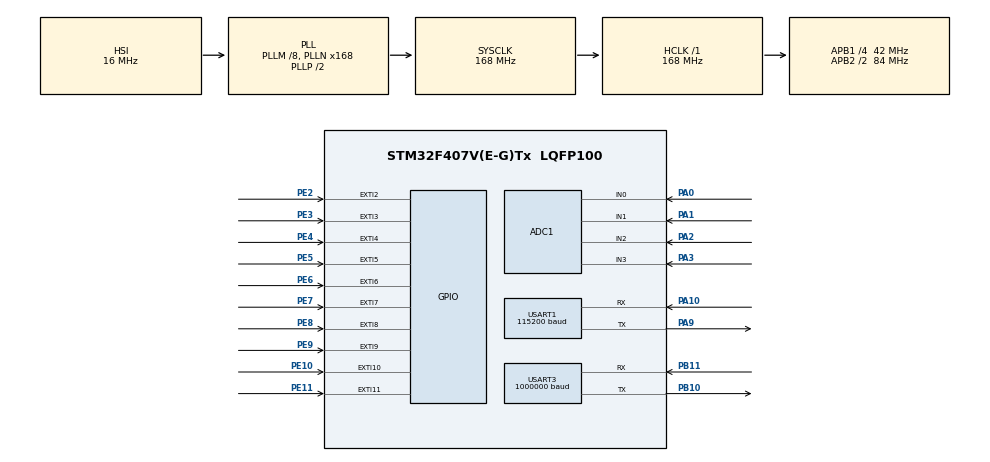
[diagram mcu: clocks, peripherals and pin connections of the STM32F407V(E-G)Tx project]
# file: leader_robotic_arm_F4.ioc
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ADC1.Channel-0\#ChannelRegularConversion=ADC_CHANNEL_0
ADC1.Channel-1\#ChannelRegularConversion=ADC_CHANNEL_1
ADC1.Channel-2\#ChannelRegularConversion=ADC_CHANNEL_2
ADC1.Channel-3\#ChannelRegularConversion=ADC_CHANNEL_3
ADC1.ContinuousConvMode=ENABLE
ADC1.DMAContinuousRequests=ENABLE
ADC1.NbrOfConversion=4
ADC1.NbrOfConversionFlag=1
ADC1.Rank-0\#ChannelRegularConversion=1
ADC1.Rank-1\#ChannelRegularConversion=2
ADC1.Rank-2\#ChannelRegularConversion=3
ADC1.Rank-3\#ChannelRegularConversion=4
ADC1.SamplingTime-0\#ChannelRegularConversion=ADC_SAMPLETIME_28CYCLES
ADC1.SamplingTime-1\#ChannelRegularConversion=ADC_SAMPLETIME_28CYCLES
ADC1.SamplingTime-2\#ChannelRegularConversion=ADC_SAMPLETIME_28CYCLES
ADC1.SamplingTime-3\#ChannelRegularConversion=ADC_SAMPLETIME_28CYCLES
ADC1.master=1
Dma.ADC1.0.Direction=DMA_PERIPH_TO_MEMORY
Dma.ADC1.0.FIFOMode=DMA_FIFOMODE_DISABLE
Dma.ADC1.0.Instance=DMA2_Stream0
Dma.ADC1.0.MemDataAlignment=DMA_MDATAALIGN_HALFWORD
Dma.ADC1.0.MemInc=DMA_MINC_ENABLE
Dma.ADC1.0.Mode=DMA_CIRCULAR
Dma.ADC1.0.PeriphDataAlignment=DMA_PDATAALIGN_HALFWORD
Dma.ADC1.0.PeriphInc=DMA_PINC_DISABLE
Dma.ADC1.0.Priority=DMA_PRIORITY_HIGH
Dma.Request0=ADC1
Mcu.Family=STM32F4
Mcu.Name=STM32F407V(E-G)Tx
Mcu.Package=LQFP100
NVIC.DMA2_Stream0_IRQn=true\:0\:0\:false\:false\:true\:false\:true\:true
NVIC.EXTI15_10_IRQn=true\:0\:0\:false\:false\:true\:true\:true\:true
NVIC.EXTI2_IRQn=true\:0\:0\:false\:false\:true\:true\:true\:true
NVIC.EXTI3_IRQn=true\:0\:0\:false\:false\:true\:true\:true\:true
NVIC.EXTI4_IRQn=true\:0\:0\:false\:false\:true\:true\:true\:true
NVIC.EXTI9_5_IRQn=true\:0\:0\:false\:false\:true\:true\:true\:true
NVIC.PriorityGroup=NVIC_PRIORITYGROUP_4
NVIC.USART1_IRQn=true\:0\:0\:false\:false\:true\:true\:true\:true
NVIC.USART3_IRQn=true\:0\:0\:false\:false\:true\:true\:true\:true
PA0-WKUP.Signal=ADCx_IN0
PA1.Signal=ADCx_IN1
PA10.Mode=Asynchronous
PA10.Signal=USART1_RX
PA13.Mode=Serial_Wire
PA13.Signal=SYS_JTMS-SWDIO
PA14.Mode=Serial_Wire
PA14.Signal=SYS_JTCK-SWCLK
PA2.Signal=ADCx_IN2
PA3.Signal=ADCx_IN3
PA9.Mode=Asynchronous
PA9.Signal=USART1_TX
PB10.Mode=Asynchronous
PB10.Signal=USART3_TX
PB11.Mode=Asynchronous
PB11.Signal=USART3_RX
PE10.GPIO_ModeDefaultEXTI=GPIO_MODE_IT_RISING_FALLING
PE10.GPIO_PuPd=GPIO_PULLUP
PE10.Signal=GPXTI10
PE11.GPIO_ModeDefaultEXTI=GPIO_MODE_IT_RISING_FALLING
PE11.GPIO_PuPd=GPIO_PULLUP
PE11.Signal=GPXTI11
PE2.GPIO_ModeDefaultEXTI=GPIO_MODE_IT_RISING_FALLING
PE2.GPIO_PuPd=GPIO_PULLUP
PE2.Signal=GPXTI2
PE3.GPIO_ModeDefaultEXTI=GPIO_MODE_IT_RISING_FALLING
PE3.GPIO_PuPd=GPIO_PULLUP
PE3.Signal=GPXTI3
PE4.GPIO_ModeDefaultEXTI=GPIO_MODE_IT_RISING_FALLING
PE4.GPIO_PuPd=GPIO_PULLUP
PE4.Signal=GPXTI4
PE5.GPIO_ModeDefaultEXTI=GPIO_MODE_IT_RISING_FALLING
PE5.GPIO_PuPd=GPIO_PULLUP
PE5.Signal=GPXTI5
PE6.GPIO_ModeDefaultEXTI=GPIO_MODE_IT_RISING_FALLING
PE6.GPIO_PuPd=GPIO_PULLUP
PE6.Signal=GPXTI6
PE7.GPIO_ModeDefaultEXTI=GPIO_MODE_IT_RISING_FALLING
PE7.GPIO_PuPd=GPIO_PULLUP
PE7.Signal=GPXTI7
PE8.GPIO_ModeDefaultEXTI=GPIO_MODE_IT_RISING_FALLING
PE8.GPIO_PuPd=GPIO_PULLUP
PE8.Signal=GPXTI8
PE9.GPIO_ModeDefaultEXTI=GPIO_MODE_IT_RISING_FALLING
PE9.GPIO_PuPd=GPIO_PULLUP
PE9.Signal=GPXTI9
PH0-OSC_IN.Mode=HSE-External-Oscillator
PH0-OSC_IN.Signal=RCC_OSC_IN
PH1-OSC_OUT.Mode=HSE-External-Oscillator
PH1-OSC_OUT.Signal=RCC_OSC_OUT
ProjectManager.HeapSize=0x200
ProjectManager.StackSize=0x400
ProjectManager.TargetToolchain=CMake
RCC.48MHZClocksFreq_Value=84000000
RCC.AHBFreq_Value=168000000
RCC.APB1CLKDivider=RCC_HCLK_DIV4
RCC.APB1Freq_Value=42000000
RCC.APB1TimFreq_Value=84000000
RCC.APB2CLKDivider=RCC_HCLK_DIV2
RCC.APB2Freq_Value=84000000
RCC.APB2TimFreq_Value=168000000
RCC.CortexFreq_Value=168000000
RCC.FLatency=FLASH_LATENCY_5
RCC.HCLKFreq_Value=168000000
RCC.HSE_VALUE=25000000
RCC.HSI_VALUE=16000000
RCC.LSE_VALUE=32768
RCC.PLLM=8
RCC.PLLN=168
RCC.SYSCLKFreq_VALUE=168000000
RCC.SYSCLKSource=RCC_SYSCLKSOURCE_PLLCLK
RCC.VCOOutputFreq_Value=336000000
SH.ADCx_IN0.0=ADC1_IN0,IN0
SH.ADCx_IN1.0=ADC1_IN1,IN1
SH.ADCx_IN2.0=ADC1_IN2,IN2
SH.ADCx_IN3.0=ADC1_IN3,IN3
USART1.BaudRate=115200
USART1.Mode=MODE_TX_RX
USART1.Parity=PARITY_NONE
USART1.StopBits=STOPBITS_1
USART1.VirtualMode=VM_ASYNC
USART1.WordLength=WORDLENGTH_8B
USART3.BaudRate=1000000
USART3.VirtualMode=VM_ASYNC
board=custom

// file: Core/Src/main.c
/* USER CODE BEGIN Header */
/**
  ******************************************************************************
  * @file           : main.c
  * @brief          : Main program body
  ******************************************************************************
  * @attention
  *
  * Copyright (c) 2026 STMicroelectronics.
  * All rights reserved.
  *
  * This software is licensed under terms that can be found in the LICENSE file
  * in the root directory of this software component.
  * If no LICENSE file comes with this software, it is provided AS-IS.
  *
  ******************************************************************************
  */
/* USER CODE END Header */
#include "main.h"
#include "adc.h"
#include "dma.h"
#include "usart.h"
#include "gpio.h"

/* USER CODE BEGIN Includes */
#include "control_task.h"
#include <stdint.h>
/* USER CODE END Includes */

void SystemClock_Config(void);

int main(void)
{

  /* MCU Configuration--------------------------------------------------------*/

  /* Reset of all peripherals, Initializes the Flash interface and the Systick. */
  HAL_Init();

  /* Configure the system clock */
  SystemClock_Config();

  /* Initialize all configured peripherals */
  MX_GPIO_Init();
  MX_DMA_Init();
  MX_USART1_UART_Init();
  MX_ADC1_Init();
  MX_USART3_UART_Init();
  /* USER CODE BEGIN 2 */

  control_task_init();

  /* USER CODE END 2 */

  /* Infinite loop */
  /* USER CODE BEGIN WHILE */
  while (1)
  {
    int start_time = HAL_GetTick();

    control_task_update();

    /* USER CODE END WHILE */

    /* USER CODE BEGIN 3 */
    int sleep_time = 1/60.0*1000 - (HAL_GetTick() - start_time);
    if(sleep_time > 0)
    {
        HAL_Delay( sleep_time);
    }
  }
  /* USER CODE END 3 */
}

void SystemClock_Config(void)
{
  RCC_OscInitTypeDef RCC_OscInitStruct = {0};
  RCC_ClkInitTypeDef RCC_ClkInitStruct = {0};

  /** Configure the main internal regulator output voltage
  */
  __HAL_RCC_PWR_CLK_ENABLE();
  __HAL_PWR_VOLTAGESCALING_CONFIG(PWR_REGULATOR_VOLTAGE_SCALE1);

  /** Initializes the RCC Oscillators according to the specified parameters
  * in the RCC_OscInitTypeDef structure.
  */
  RCC_OscInitStruct.OscillatorType = RCC_OSCILLATORTYPE_HSI;
  RCC_OscInitStruct.HSIState = RCC_HSI_ON;
  RCC_OscInitStruct.HSICalibrationValue = RCC_HSICALIBRATION_DEFAULT;
  RCC_OscInitStruct.PLL.PLLState = RCC_PLL_ON;
  RCC_OscInitStruct.PLL.PLLSource = RCC_PLLSOURCE_HSI;
  RCC_OscInitStruct.PLL.PLLM = 8;
  RCC_OscInitStruct.PLL.PLLN = 168;
  RCC_OscInitStruct.PLL.PLLP = RCC_PLLP_DIV2;
  RCC_OscInitStruct.PLL.PLLQ = 4;
  if (HAL_RCC_OscConfig(&RCC_OscInitStruct) != HAL_OK)
  {
    Error_Handler();
  }

  /** Initializes the CPU, AHB and APB buses clocks
  */
  RCC_ClkInitStruct.ClockType = RCC_CLOCKTYPE_HCLK|RCC_CLOCKTYPE_SYSCLK
                              |RCC_CLOCKTYPE_PCLK1|RCC_CLOCKTYPE_PCLK2;
  RCC_ClkInitStruct.SYSCLKSource = RCC_SYSCLKSOURCE_PLLCLK;
  RCC_ClkInitStruct.AHBCLKDivider = RCC_SYSCLK_DIV1;
  RCC_ClkInitStruct.APB1CLKDivider = RCC_HCLK_DIV4;
  RCC_ClkInitStruct.APB2CLKDivider = RCC_HCLK_DIV2;

  if (HAL_RCC_ClockConfig(&RCC_ClkInitStruct, FLASH_LATENCY_5) != HAL_OK)
  {
    Error_Handler();
  }
}

void Error_Handler(void)
{
  __disable_irq();
  while (1)
  {
  }
}
